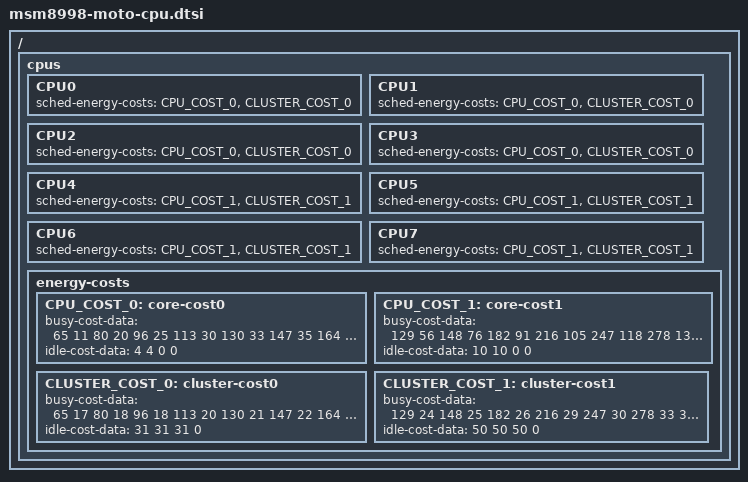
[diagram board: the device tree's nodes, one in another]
/* Copyright (c) 2015-2016, The Linux Foundation. All rights reserved.
 *
 * This program is free software; you can redistribute it and/or modify
 * it under the terms of the GNU General Public License version 2 and
 * only version 2 as published by the Free Software Foundation.
 *
 * This program is distributed in the hope that it will be useful,
 * but WITHOUT ANY WARRANTY; without even the implied warranty of
 * MERCHANTABILITY or FITNESS FOR A PARTICULAR PURPOSE.  See the
 * GNU General Public License for more details.
 */

/ {
	cpus {
		CPU0 {
			sched-energy-costs = <&CPU_COST_0 &CLUSTER_COST_0>;
		};
		CPU1 {
			sched-energy-costs = <&CPU_COST_0 &CLUSTER_COST_0>;
		};
		CPU2 {
			sched-energy-costs = <&CPU_COST_0 &CLUSTER_COST_0>;
		};
		CPU3 {
			sched-energy-costs = <&CPU_COST_0 &CLUSTER_COST_0>;
		};
		CPU4 {
			sched-energy-costs = <&CPU_COST_1 &CLUSTER_COST_1>;
		};
		CPU5 {
			sched-energy-costs = <&CPU_COST_1 &CLUSTER_COST_1>;
		};
		CPU6 {
			sched-energy-costs = <&CPU_COST_1 &CLUSTER_COST_1>;
		};
		CPU7 {
			sched-energy-costs = <&CPU_COST_1 &CLUSTER_COST_1>;
		};
		energy-costs {
			CPU_COST_0: core-cost0 {
				busy-cost-data = <
					65  11
					80  20
					96  25
					113 30
					130 33
					147 35
					164 36
					181 42
					194 47
					211 54
					228 62
					243 67
					258 73
					275 79
					292 88
					308 95
					326 104
					342 111
					368 134
					384 155
					401 178
					419 201
				>;
				idle-cost-data = <
					4 4 0 0
				>;
			};
			CPU_COST_1: core-cost1 {
				busy-cost-data = <
					129  56
					148  76
					182  91
					216  105
					247  118
					278  135
					312  150
					344  162
					391  181
					419  196
					453  214
					487  229
					509  248
					546  280
					581  316
					615  354
					650  392
					676  439
					712  495
					739  565
					776  622
					803  691
					834  792
					881  889
					914  1059
					957  1244
					975  1375
					996  1549
					1016 1617
					1021 1677
					1024 1683
				>;

				idle-cost-data = <
				      10 10 0 0
				>;
			};
			CLUSTER_COST_0: cluster-cost0 {
				busy-cost-data = <
					65  17
					80  18
					96  18
					113 20
					130 21
					147 22
					164 23
					181 24
					194 27
					211 29
					228 30
					243 32
					258 33
					275 35
					292 38
					308 39
					326 42
					342 46
					368 48
					384 53
					401 59
					419 66
				>;
				idle-cost-data = <
					31 31 31 0
				>;
			};
			CLUSTER_COST_1: cluster-cost1 {
				busy-cost-data = <
					129  24
					148  25
					182  26
					216  29
					247  30
					278  33
					312  35
					344  37
					391  38
					419  40
					453  43
					487  44
					509  46
					546  50
					581  54
					615  60
					650  63
					676  70
					712  74
					739  80
					776  87
					803  96
					834  104
					881  120
					914  130
					957  171
					975  178
					996  185
					1016 200
					1021 202
					1024 203
				>;
				idle-cost-data = <
					50 50 50 0
				>;
			};
		};
	};
};
